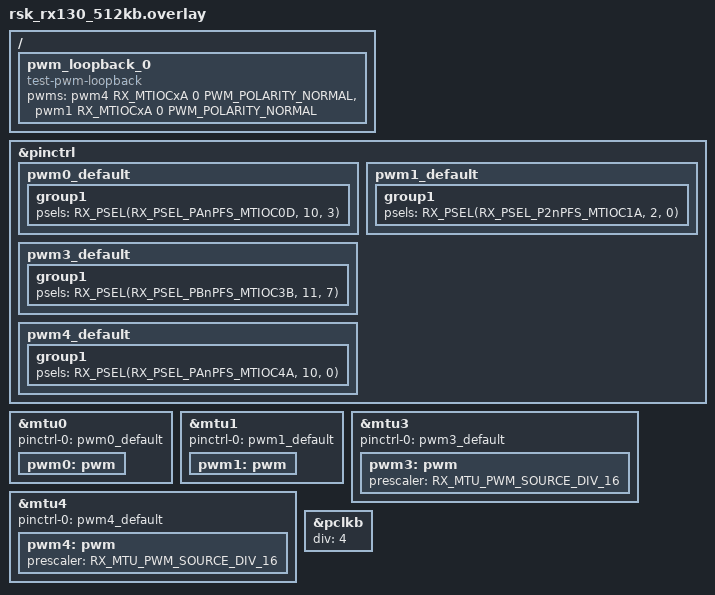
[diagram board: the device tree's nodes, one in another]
/*
 * Copyright (c) 2024 Renesas Electronics Corporation
 *
 * SPDX-License-Identifier: Apache-2.0
 */

#include <zephyr/dt-bindings/pwm/pwm.h>
#include <zephyr/dt-bindings/pwm/rx_mtu_pwm.h>

/ {
	pwm_loopback_0 {
		compatible = "test-pwm-loopback";
		pwms =<&pwm4 RX_MTIOCxA 0 PWM_POLARITY_NORMAL>,
		 <&pwm1 RX_MTIOCxA 0 PWM_POLARITY_NORMAL>;
	};
};

&pinctrl {
	pwm0_default: pwm0_default {
		group1 {
			psels = <RX_PSEL(RX_PSEL_PAnPFS_MTIOC0D, 10, 3)>;
		};
	};

	pwm1_default: pwm1_default {
		group1 {
			psels = <RX_PSEL(RX_PSEL_P2nPFS_MTIOC1A, 2, 0)>;
		};
	};

	pwm3_default: pwm3_default {
		group1 {
			psels = <RX_PSEL(RX_PSEL_PBnPFS_MTIOC3B, 11, 7)>;
		};
	};

	pwm4_default: pwm4_default {
		group1 {
			psels = <RX_PSEL(RX_PSEL_PAnPFS_MTIOC4A, 10, 0)>;
		};
	};
};

&mtu0 {
	status = "okay";
	pinctrl-0 = <&pwm0_default>;
	pinctrl-names = "default";
	pwm0: pwm {
		status = "okay";
	};
};

&mtu1 {
	status = "okay";
	pinctrl-0 = <&pwm1_default>;
	pinctrl-names = "default";
	pwm1: pwm {
		status = "okay";
	};
};

&mtu3 {
	status = "okay";
	pinctrl-0 = <&pwm3_default>;
	pinctrl-names = "default";
	pwm3: pwm {
		status = "okay";
		prescaler = <RX_MTU_PWM_SOURCE_DIV_16>;
	};
};

&mtu4 {
	status = "okay";
	pinctrl-0 = <&pwm4_default>;
	pinctrl-names = "default";
	pwm4: pwm {
		status = "okay";
		prescaler = <RX_MTU_PWM_SOURCE_DIV_16>;
	};
};


&pclkb {
	div = <4>;
};
